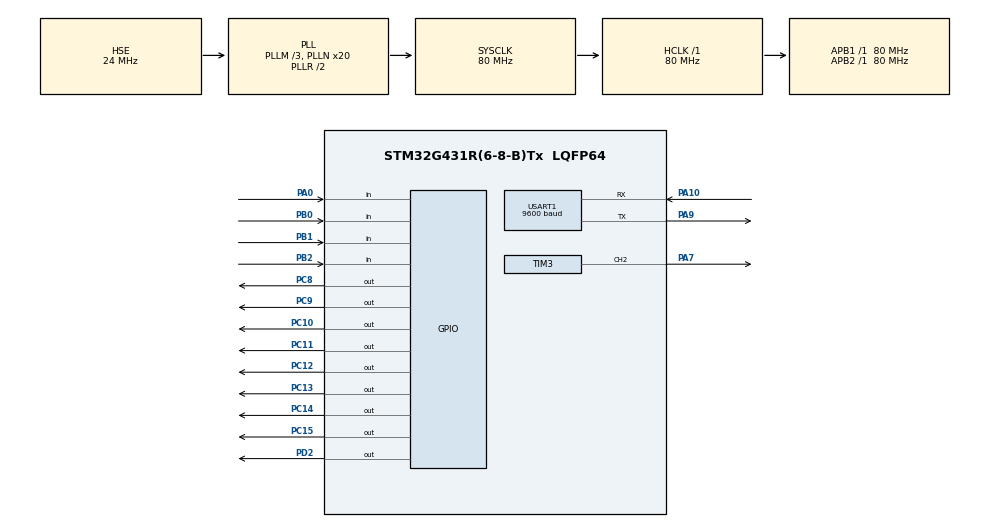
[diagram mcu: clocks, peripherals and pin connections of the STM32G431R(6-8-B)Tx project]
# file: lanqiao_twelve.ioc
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Mcu.Family=STM32G4
Mcu.Name=STM32G431R(6-8-B)Tx
Mcu.Package=LQFP64
NVIC.PriorityGroup=NVIC_PRIORITYGROUP_4
NVIC.TIM3_IRQn=true\:0\:0\:false\:false\:true\:true\:true\:true
NVIC.USART1_IRQn=true\:0\:0\:false\:false\:true\:true\:true\:true
PA0.Signal=GPIO_Input
PA10.Mode=Asynchronous
PA10.Signal=USART1_RX
PA7.Signal=S_TIM3_CH2
PA9.Mode=Asynchronous
PA9.Signal=USART1_TX
PB0.Signal=GPIO_Input
PB1.Signal=GPIO_Input
PB2.Signal=GPIO_Input
PC10.GPIO_ModeDefaultOutputPP=GPIO_MODE_OUTPUT_PP
PC10.GPIO_PuPd=GPIO_NOPULL
PC10.GPIO_Speed=GPIO_SPEED_FREQ_LOW
PC10.PinState=GPIO_PIN_SET
PC10.Signal=GPIO_Output
PC11.GPIO_ModeDefaultOutputPP=GPIO_MODE_OUTPUT_PP
PC11.GPIO_PuPd=GPIO_NOPULL
PC11.GPIO_Speed=GPIO_SPEED_FREQ_LOW
PC11.PinState=GPIO_PIN_SET
PC11.Signal=GPIO_Output
PC12.GPIO_ModeDefaultOutputPP=GPIO_MODE_OUTPUT_PP
PC12.GPIO_PuPd=GPIO_NOPULL
PC12.GPIO_Speed=GPIO_SPEED_FREQ_LOW
PC12.PinState=GPIO_PIN_SET
PC12.Signal=GPIO_Output
PC13.GPIO_ModeDefaultOutputPP=GPIO_MODE_OUTPUT_PP
PC13.GPIO_PuPd=GPIO_NOPULL
PC13.GPIO_Speed=GPIO_SPEED_FREQ_LOW
PC13.PinState=GPIO_PIN_SET
PC13.Signal=GPIO_Output
PC14-OSC32_IN.GPIO_ModeDefaultOutputPP=GPIO_MODE_OUTPUT_PP
PC14-OSC32_IN.GPIO_PuPd=GPIO_NOPULL
PC14-OSC32_IN.GPIO_Speed=GPIO_SPEED_FREQ_LOW
PC14-OSC32_IN.PinState=GPIO_PIN_SET
PC14-OSC32_IN.Signal=GPIO_Output
PC15-OSC32_OUT.GPIO_ModeDefaultOutputPP=GPIO_MODE_OUTPUT_PP
PC15-OSC32_OUT.GPIO_PuPd=GPIO_NOPULL
PC15-OSC32_OUT.GPIO_Speed=GPIO_SPEED_FREQ_LOW
PC15-OSC32_OUT.PinState=GPIO_PIN_SET
PC15-OSC32_OUT.Signal=GPIO_Output
PC8.GPIO_ModeDefaultOutputPP=GPIO_MODE_OUTPUT_PP
PC8.GPIO_PuPd=GPIO_NOPULL
PC8.GPIO_Speed=GPIO_SPEED_FREQ_LOW
PC8.PinState=GPIO_PIN_SET
PC8.Signal=GPIO_Output
PC9.GPIO_ModeDefaultOutputPP=GPIO_MODE_OUTPUT_PP
PC9.GPIO_PuPd=GPIO_NOPULL
PC9.GPIO_Speed=GPIO_SPEED_FREQ_LOW
PC9.PinState=GPIO_PIN_SET
PC9.Signal=GPIO_Output
PD2.Signal=GPIO_Output
PF0-OSC_IN.Mode=HSE-External-Oscillator
PF0-OSC_IN.Signal=RCC_OSC_IN
PF1-OSC_OUT.Mode=HSE-External-Oscillator
PF1-OSC_OUT.Signal=RCC_OSC_OUT
ProjectManager.HeapSize=0x200
ProjectManager.StackSize=0x400
ProjectManager.TargetToolchain=MDK-ARM V5.32
RCC.ADC12Freq_Value=80000000
RCC.AHBFreq_Value=80000000
RCC.APB1Freq_Value=80000000
RCC.APB1TimFreq_Value=80000000
RCC.APB2Freq_Value=80000000
RCC.APB2TimFreq_Value=80000000
RCC.CortexFreq_Value=80000000
RCC.EXTERNAL_CLOCK_VALUE=12288000
RCC.HCLKFreq_Value=80000000
RCC.HSE_VALUE=24000000
RCC.HSI48_VALUE=48000000
RCC.HSI_VALUE=16000000
RCC.LSE_VALUE=32768
RCC.PLLM=RCC_PLLM_DIV3
RCC.PLLN=20
RCC.PLLSourceVirtual=RCC_PLLSOURCE_HSE
RCC.SYSCLKFreq_VALUE=80000000
RCC.SYSCLKSource=RCC_SYSCLKSOURCE_PLLCLK
RCC.USBFreq_Value=80000000
RCC.VCOOutputFreq_Value=160000000
SH.S_TIM3_CH2.0=TIM3_CH2,PWM Generation2 CH2
TIM3.Channel-PWM\ Generation2\ CH2=TIM_CHANNEL_2
TIM3.PeriodNoDither=499
TIM3.Prescaler=79
TIM3.PulseNoDither_2=99
USART1.BaudRate=9600
USART1.VirtualMode-Asynchronous=VM_ASYNC
VP_SYS_VS_DBSignals.Mode=DisableDeadBatterySignals
VP_TIM3_VS_ClockSourceINT.Mode=Internal
board=custom

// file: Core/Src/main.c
/* USER CODE BEGIN Header */
/**
  ******************************************************************************
  * @file           : main.c
  * @brief          : Main program body
  ******************************************************************************
  * @attention
  *
  * Copyright (c) 2024 STMicroelectronics.
  * All rights reserved.
  *
  * This software is licensed under terms that can be found in the LICENSE file
  * in the root directory of this software component.
  * If no LICENSE file comes with this software, it is provided AS-IS.
  *
  ******************************************************************************
  */
/* USER CODE END Header */
#include "main.h"
#include "tim.h"
#include "usart.h"
#include "gpio.h"
#include "BSP_TEST.h"
#include "BSP_key.h"
#include "BSP_led.h"
#include "lcd.h"
#include "stdio.h"

void SystemClock_Config(void);

int main(void)
{

  /* MCU Configuration--------------------------------------------------------*/

  /* Reset of all peripherals, Initializes the Flash interface and the Systick. */
  HAL_Init();

  /* Configure the system clock */
  SystemClock_Config();

  /* Initialize all configured peripherals */
  MX_GPIO_Init();
  MX_TIM3_Init();
  MX_USART1_UART_Init();
  /* USER CODE BEGIN 2 */
  LCD_Init();
	HAL_UART_Receive_IT(&huart1, &Usart1_RxData_Temp, 1);
  /* USER CODE END 2 */

  /* Infinite loop */
  /* USER CODE BEGIN WHILE */
	sprintf((char *)Uart1_Tx_Buf, " hello world!20240116\r\n");  //注意需要头文件："stdio.h"
  HAL_UART_Transmit(&huart1,Uart1_Tx_Buf,30,1000);	//发送接收到的数据
  chewei_jiemian();
	led_state = 0x01;
	led_control(led_state);//led2控制
  while (1)
  {
		Key_Proc();
		UART_Proc();
    /* USER CODE END WHILE */

  }
}

void SystemClock_Config(void)
{
  RCC_OscInitTypeDef RCC_OscInitStruct = {0};
  RCC_ClkInitTypeDef RCC_ClkInitStruct = {0};

  /** Configure the main internal regulator output voltage
  */
  HAL_PWREx_ControlVoltageScaling(PWR_REGULATOR_VOLTAGE_SCALE1);

  /** Initializes the RCC Oscillators according to the specified parameters
  * in the RCC_OscInitTypeDef structure.
  */
  RCC_OscInitStruct.OscillatorType = RCC_OSCILLATORTYPE_HSE;
  RCC_OscInitStruct.HSEState = RCC_HSE_ON;
  RCC_OscInitStruct.PLL.PLLState = RCC_PLL_ON;
  RCC_OscInitStruct.PLL.PLLSource = RCC_PLLSOURCE_HSE;
  RCC_OscInitStruct.PLL.PLLM = RCC_PLLM_DIV3;
  RCC_OscInitStruct.PLL.PLLN = 20;
  RCC_OscInitStruct.PLL.PLLP = RCC_PLLP_DIV2;
  RCC_OscInitStruct.PLL.PLLQ = RCC_PLLQ_DIV2;
  RCC_OscInitStruct.PLL.PLLR = RCC_PLLR_DIV2;
  if (HAL_RCC_OscConfig(&RCC_OscInitStruct) != HAL_OK)
  {
    Error_Handler();
  }

  /** Initializes the CPU, AHB and APB buses clocks
  */
  RCC_ClkInitStruct.ClockType = RCC_CLOCKTYPE_HCLK|RCC_CLOCKTYPE_SYSCLK
                              |RCC_CLOCKTYPE_PCLK1|RCC_CLOCKTYPE_PCLK2;
  RCC_ClkInitStruct.SYSCLKSource = RCC_SYSCLKSOURCE_PLLCLK;
  RCC_ClkInitStruct.AHBCLKDivider = RCC_SYSCLK_DIV1;
  RCC_ClkInitStruct.APB1CLKDivider = RCC_HCLK_DIV1;
  RCC_ClkInitStruct.APB2CLKDivider = RCC_HCLK_DIV1;

  if (HAL_RCC_ClockConfig(&RCC_ClkInitStruct, FLASH_LATENCY_2) != HAL_OK)
  {
    Error_Handler();
  }
}

void Error_Handler(void)
{
  __disable_irq();
  while (1)
  {
  }
}
